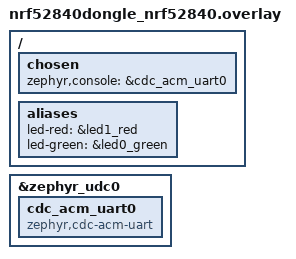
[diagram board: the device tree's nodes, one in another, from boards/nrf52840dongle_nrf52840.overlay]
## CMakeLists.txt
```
cmake_minimum_required(VERSION 3.20.0)

list(APPEND ZEPHYR_EXTRA_MODULES
	"${CMAKE_CURRENT_SOURCE_DIR}/../../libs/cookie_proto"
)

list(APPEND BOARD_ROOT "${CMAKE_CURRENT_SOURCE_DIR}/../..")
list(APPEND DTS_ROOT   "${CMAKE_CURRENT_SOURCE_DIR}/../..")

find_package(Zephyr REQUIRED HINTS $ENV{ZEPHYR_BASE})
project(cookie_gateway)

target_sources(app PRIVATE
	src/main.c
	src/coap_server.c
	src/usb_print.c
)
```

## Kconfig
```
mainmenu "Cookie gateway"

# Thread network credentials live in upstream Kconfig:
#   CONFIG_OPENTHREAD_NETWORK_NAME
#   CONFIG_OPENTHREAD_NETWORKKEY
#   CONFIG_OPENTHREAD_PANID
#   CONFIG_OPENTHREAD_XPANID
#   CONFIG_OPENTHREAD_CHANNEL
# Defaults are set in apps/gateway/prj.conf.

source "Kconfig.zephyr"
```

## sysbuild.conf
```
SB_CONFIG_BOOTLOADER_MCUBOOT=n

# Disable Partition Manager: it's deprecated in NCS v3.3 and was the actual
# cause of the SYS_INIT crash that killed every OpenThread image on
# nRF52840 Dongle. Without PM, Zephyr uses the DT-declared partitions.
SB_CONFIG_PARTITION_MANAGER=n
```

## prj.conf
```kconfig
# Cookie gateway: OpenThread FTD + Zephyr CoAP server + raw passthrough to
# the host console.
#
# Builds on both nrf52840dongle (USB-CDC console) and cookie_nrf_v200
# (hardware UART console). Per-board specifics live in
# boards/<board>.conf. CONFIG_OPENTHREAD=y pulls in the OT stack;
# Zephyr-side NETWORKING/L2/sockets/CoAP are added because the gateway
# uses Zephyr's <zephyr/net/coap.h> + BSD sockets (not OT's CoAP API).
# OT defaults auto-start; the dataset comes from CONFIG_OPENTHREAD_NETWORK*
# below.

# Core OpenThread.
CONFIG_OPENTHREAD=y

# Zephyr networking (selected explicitly; CONFIG_OPENTHREAD does not pull these
# transitively).
CONFIG_NETWORKING=y
CONFIG_NET_L2_OPENTHREAD=y
CONFIG_NET_IPV6=y
CONFIG_NET_UDP=y
CONFIG_NET_SOCKETS=y

# OT-native CoAP (replaces the Zephyr CoAP-over-socket path used in the
# old coap_server.c — Zephyr's socket layer doesn't surface multicast on
# the OT-backed stack).
CONFIG_OPENTHREAD_COAP=y

# Default Thread dataset (baked in; auto-loaded by Zephyr glue at boot).
CONFIG_OPENTHREAD_NETWORK_NAME="CookieMesh"
CONFIG_OPENTHREAD_NETWORKKEY="00:11:22:33:44:55:66:77:88:99:aa:bb:cc:dd:ee:ff"
CONFIG_OPENTHREAD_PANID=43981
CONFIG_OPENTHREAD_XPANID="de:ad:00:be:ef:00:ca:fe"
CONFIG_OPENTHREAD_CHANNEL=15

# As the headline gateway image we want to bias toward Leader/Router; bump the
# Router upgrade threshold so an early-booted Cookie gateway snaps up the
# Leader role rather than hanging at REED.
CONFIG_OPENTHREAD_MAX_CHILDREN=10

# Settings storage for OT dataset persistence.
CONFIG_PM_PARTITION_SIZE_SETTINGS_STORAGE=0x8000

# Trim mbedtls (saves ~5 KB; we don't use SHA-1 anywhere).
CONFIG_MBEDTLS_SHA1_C=n

# Console / printk for raw JSON-line emission.
# LOG_MODE_DEFERRED so the log subsystem doesn't block USB enumeration in
# SYS_INIT (IMMEDIATE mode can hang the Dongle gateway there).
CONFIG_LOG=y
CONFIG_LOG_MODE_DEFERRED=y
CONFIG_PRINTK=y
CONFIG_GPIO=y
CONFIG_CBPRINTF_FP_SUPPORT=y
CONFIG_FPU=y

# Thread-side logging kept to critical only: at INFO/DEBUG the Mle and
# MeshForwarder spam floods the console, overruns the deferred log buffer and
# truncates the JSON frames the PC tool parses. Frames (printk) also bypass the
# log subsystem so they reach the console intact regardless of log pressure.
CONFIG_OPENTHREAD_LOG_LEVEL_CRIT=y
CONFIG_OPENTHREAD_DEBUG=n
CONFIG_LOG_PRINTK=n

# Stack and main thread.
CONFIG_MAIN_STACK_SIZE=4096

# Cookie shared protocol library (frame schema, resource paths).
CONFIG_COOKIE_PROTO=y
```

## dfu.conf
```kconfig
# DFU image layout: the Nordic Open Bootloader keeps a static MBR in the first
# 4 kB of flash and its own USB bootloader at the top, so the application is
# linked at 0x1000 and handed to the board over USB with nrfutil instead of SWD.
#
# Layered on top of usb_console.conf: a gateway flashed over its own USB-C is
# also read over its own USB-C. Pairs with dfu.overlay, which moves the
# settings storage partition clear of the bootloader region at the top of
# flash.

# No MCUboot in this project (see sysbuild.conf), so the code partition in
# devicetree does not describe this image. Take the load offset from Kconfig.
CONFIG_USE_DT_CODE_PARTITION=n
CONFIG_FLASH_LOAD_OFFSET=0x1000

# The bootloader treats 0xDD000-0xDFFFF as application data: it never erases
# those pages during DFU and rejects any image that reaches past 0xDD000.
# Cap the link region so an oversized image fails at build time, not on DFU.
CONFIG_FLASH_LOAD_SIZE=0xDC000
```

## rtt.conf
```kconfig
# Single-board bring-up: route console + logging to SEGGER RTT so the
# gateway JSON-line stream and logs are read over the same J-Link/SWD probe,
# with no UART-to-USB bridge wired. The PC tool reads the RTT channel.
CONFIG_USE_SEGGER_RTT=y
CONFIG_CONSOLE=y
CONFIG_RTT_CONSOLE=y
CONFIG_UART_CONSOLE=n
CONFIG_LOG_BACKEND_RTT=y
CONFIG_LOG_BACKEND_UART=n
CONFIG_SEGGER_RTT_BUFFER_SIZE_UP=4096

# Bare-metal SWD flashing without a bootloader: the board defconfig pins
# USE_DT_CODE_PARTITION=y (image linked at slot0 = 0xC000, expecting MCUboot
# at 0x0). With no bootloader present the chip reads a blank vector table at
# 0x0 and HardFaults. Link the image at flash base 0x0 instead.
CONFIG_USE_DT_CODE_PARTITION=n
```

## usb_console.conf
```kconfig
# USB-CDC ACM console for the Cookie gateway / border router (read the whole
# mesh directly over the board's own USB-C as a COM port, no J-Link / RTT).
#
# The gateway already emits forwarded sensor frames, topology events and a
# heartbeat via printk (apps/gateway/src). This overlay just moves the console
# from the hardware UART to a USB-CDC serial port and brings USB up at boot.
# Pairs with usb_console.overlay.

CONFIG_USB_DEVICE_STACK_NEXT=y
CONFIG_USBD_CDC_ACM_CLASS=y
CONFIG_CDC_ACM_SERIAL_INITIALIZE_AT_BOOT=y
CONFIG_CDC_ACM_SERIAL_PRODUCT_STRING="Cookie Gateway"

CONFIG_SERIAL=y
CONFIG_CONSOLE=y
CONFIG_UART_CONSOLE=y
CONFIG_UART_LINE_CTRL=y

CONFIG_HWINFO=y

# No MCUboot in this project (sysbuild.conf): link at flash base 0x0 so the
# reset vector is valid when flashed straight over SWD.
CONFIG_USE_DT_CODE_PARTITION=n
```

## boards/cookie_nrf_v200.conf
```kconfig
# Cookie nRF V2.00 as gateway / Leader.
#
# Console is the on-board hardware UART (set as zephyr,console in the
# board DTS chosen{}). No USB stack is brought up; the PC tool reads the
# JSON-line stream over UART through whatever USB-to-serial bridge sits
# next to the board (or through the SWD probe's VCOM if J-Link is used).
#
# All Cookie defconfig settings (GPIO, SERIAL, CONSOLE, UART_CONSOLE,
# clocks, MPU, hardware stack protection) are sufficient. Sensor stack is
# explicitly disabled here because the gateway image does not need it.
CONFIG_SENSOR=n
CONFIG_I2C=n
CONFIG_ADC=n
CONFIG_INPUT=n
```

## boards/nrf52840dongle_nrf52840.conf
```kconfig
# Dongle as gateway. Defconfig auto-enables USB CDC ACM as the console;
# the gateway emits its JSON-line stream there via printk (see usb_print.c).
# The product-string override below is what shows up in Device Manager
# / `lsusb -v`, so the user can tell the Cookie gateway apart from a
# vanilla Dongle on a multi-port hub.
CONFIG_CDC_ACM_SERIAL_PRODUCT_STRING="Cookie Gateway"
```

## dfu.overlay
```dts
/*
 * Settings storage relocated for the Open Bootloader layout.
 *
 * The board devicetree puts the storage partition at 0xF8000, inside the
 * region the Nordic Open Bootloader occupies (roughly 0xE0000 to 0x100000).
 * OpenThread writes its network credentials there through the settings NVS
 * backend, so on a DFU image the partition moves onto the bootloader's
 * application-data area at 0xDD000-0xDFFFF (12 kB, three NVS sectors). The
 * bootloader never erases those pages during DFU and refuses any image that
 * reaches into them, so the credentials survive a firmware update and no
 * update can clobber them.
 *
 * Pairs with dfu.conf. The unit-address of the node keeps the name it was
 * given in the board devicetree; only the address in reg is authoritative.
 */

&storage_partition {
	reg = <0x000DD000 DT_SIZE_K(12)>;
};
```

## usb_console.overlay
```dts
/*
 * USB-CDC ACM console for the Cookie gateway / border router.
 *
 * Routes the gateway console (printk: forwarded sensor frames + topology
 * events + heartbeat) to a COM port on the board's own USB-C, so the whole
 * mesh is read directly over USB with no J-Link / RTT. Pairs with
 * usb_console.conf.
 */

zephyr_udc0: &usbd {
	status = "okay";

	cdc_acm_uart0: cdc_acm_uart0 {
		compatible = "zephyr,cdc-acm-uart";
	};
};

/ {
	chosen {
		zephyr,console = &cdc_acm_uart0;
	};
};
```

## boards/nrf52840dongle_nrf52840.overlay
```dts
/ {
	chosen {
		zephyr,console = &cdc_acm_uart0;
	};

	aliases {
		led-red   = &led1_red;
		led-green = &led0_green;
	};
};

&zephyr_udc0 {
	cdc_acm_uart0: cdc_acm_uart0 {
		compatible = "zephyr,cdc-acm-uart";
	};
};
```

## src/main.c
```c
/*
 * Cookie gateway entry point.
 *
 * OpenThread is auto-started by the Zephyr glue (no MANUAL_START), with the
 * dataset taken from CONFIG_OPENTHREAD_NETWORK_NAME / NETWORKKEY / PANID /
 * XPANID / CHANNEL in prj.conf. Once the L2 is up, this module starts the
 * Zephyr CoAP server bound on UDP 5683 and toggles the green LED as a
 * heartbeat. Frame payloads are passed through verbatim to USB-CDC.
 */

#include <zephyr/kernel.h>
#include <zephyr/logging/log.h>
#include <zephyr/drivers/gpio.h>
#include <zephyr/net/openthread.h>

#include <openthread/instance.h>
#include <openthread/thread.h>
#include <openthread/link.h>

#include <stdio.h>

#include "coap_server.h"
#include "usb_print.h"

LOG_MODULE_REGISTER(gateway, LOG_LEVEL_INF);

static void ext_last4(const otExtAddress *ext, char out[5])
{
	snprintf(out, 5, "%02x%02x", ext->m8[6], ext->m8[7]);
}

/* Emit the gateway's view of the mesh as a topology event the PC tool draws:
 *   {"event":"topology","tree":{"<gw>":["<neighbour>", ...]}}
 * Node IDs are the EUI-64 last two bytes, matching the `src` field of sensor
 * frames so the tree lines up with the live table. The gateway reports its
 * direct neighbours (one radio hop); for the small demo mesh that is the whole
 * network. printk goes straight to the console (CONFIG_LOG_PRINTK=n) so the
 * line is never truncated by log-buffer pressure. */
static void emit_topology(otInstance *inst)
{
	const otExtAddress *self = otLinkGetExtendedAddress(inst);
	char gw[5];
	ext_last4(self, gw);

	char line[256];
	int off = snprintf(line, sizeof(line),
			   "{\"event\":\"topology\",\"tree\":{\"%s\":[", gw);

	otNeighborInfoIterator it = OT_NEIGHBOR_INFO_ITERATOR_INIT;
	otNeighborInfo info;
	bool first = true;
	while (off < (int)sizeof(line) - 8 &&
	       otThreadGetNextNeighborInfo(inst, &it, &info) == OT_ERROR_NONE) {
		char nb[5];
		ext_last4(&info.mExtAddress, nb);
		off += snprintf(line + off, sizeof(line) - off,
				"%s\"%s\"", first ? "" : ",", nb);
		first = false;
	}
	snprintf(line + off, sizeof(line) - off, "]}}");
	printk("%s\n", line);
}

static const struct gpio_dt_spec led_red =
	GPIO_DT_SPEC_GET_OR(DT_ALIAS(led_red), gpios, {0});
static const struct gpio_dt_spec led_green =
	GPIO_DT_SPEC_GET_OR(DT_ALIAS(led_green), gpios, {0});

static void on_thread_state_changed(otChangedFlags flags, void *user_data)
{
	ARG_UNUSED(user_data);

	if (flags & OT_CHANGED_THREAD_ROLE) {
		otDeviceRole role = otThreadGetDeviceRole(openthread_get_default_instance());
		LOG_INF("Thread role: %s", otThreadDeviceRoleToString(role));
		if (led_red.port) {
			bool attached = (role == OT_DEVICE_ROLE_LEADER ||
					 role == OT_DEVICE_ROLE_ROUTER ||
					 role == OT_DEVICE_ROLE_CHILD);
			gpio_pin_set_dt(&led_red, attached ? 1 : 0);
		}
	}
}

static struct openthread_state_changed_callback ot_state_cb = {
	.otCallback = on_thread_state_changed,
};

int main(void)
{
	LOG_INF("Cookie gateway: board=%s", CONFIG_BOARD);

	if (led_red.port) {
		gpio_pin_configure_dt(&led_red, GPIO_OUTPUT_INACTIVE);
	}
	if (led_green.port) {
		gpio_pin_configure_dt(&led_green, GPIO_OUTPUT_INACTIVE);
	}

	gateway_usb_print_init();

	/* Persistent OT state is kept across reboots so the gateway holds its
	 * partition and the mesh heals correctly per the Thread spec. The
	 * one-time clean wipe lives behind CONFIG_COOKIE_FACTORY_RESET_ON_BOOT
	 * for clearing stale datasets from earlier experiments. */
#if defined(CONFIG_COOKIE_FACTORY_RESET_ON_BOOT)
	{
		otInstance *inst = openthread_get_default_instance();
		if (inst) {
			otThreadSetEnabled(inst, false);
			otIp6SetEnabled(inst, false);
			(void)otInstanceErasePersistentInfo(inst);
			LOG_INF("OT persistent info erased (factory-reset on boot)");
		}
	}
#endif

	openthread_state_changed_callback_register(&ot_state_cb);

	int orc = openthread_run();
	if (orc) {
		LOG_ERR("openthread_run: %d", orc);
		return -1;
	}

	if (gateway_coap_server_start() != 0) {
		LOG_ERR("CoAP server start failed");
		return -1;
	}

	uint32_t tick = 0;
	while (1) {
		if (led_green.port) {
			gpio_pin_toggle_dt(&led_green);
		}
		k_sleep(K_MSEC(1000));
		if ((++tick % 5) == 0) {
			otInstance *inst = openthread_get_default_instance();
			if (inst) {
				LOG_INF("heartbeat tick=%u role=%s",
					tick,
					otThreadDeviceRoleToString(otThreadGetDeviceRole(inst)));
				emit_topology(inst);
			}
		}
	}
	return 0;
}
```

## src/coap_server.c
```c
/*
 * Stub CoAP server (#2a), now on OpenThread native CoAP API.
 *
 * Listens on UDP 5683 via OT's CoAP layer (no Zephyr socket plumbing).
 * Accepts POST /sensors/data, prints the payload as a JSON line on the
 * host console, and replies with ACK 2.04 if the request was CON.
 *
 * Why OT-native CoAP and not Zephyr CoAP-over-socket: the Zephyr UDP
 * socket bound to AF_INET6 ANY does not receive multicast packets even
 * after IPV6_ADD_MEMBERSHIP / IPV6_JOIN_GROUP / net_if_ipv6_maddr_add
 * (all return ENOTSUP / NULL on the OT-backed stack). OT's CoAP layer
 * subscribes to the right Thread groups internally and surfaces every
 * matching request to our handler.
 *
 * #4 will replace this handler with one that parses the frame, decorates
 * with ts_host, emits structured event lines, etc. The interface stays
 * compatible (single-resource registration is the public surface).
 */

#include "coap_server.h"
#include "usb_print.h"

#include <cookie_proto/resources.h>

#include <zephyr/kernel.h>
#include <zephyr/logging/log.h>
#include <zephyr/net/openthread.h>

#include <openthread/coap.h>
#include <openthread/error.h>
#include <openthread/instance.h>
#include <openthread/message.h>

#include <errno.h>
#include <string.h>

LOG_MODULE_REGISTER(coap_server, LOG_LEVEL_INF);

#define COAP_PORT      5683
#define MAX_PAYLOAD    512

static otCoapResource sensors_resource = {
	.mUriPath = COOKIE_RESOURCE_SENSORS_PATH,   /* "sensors/data" */
	.mHandler = NULL,                            /* set in start() */
	.mContext = NULL,
	.mNext    = NULL,
};

/* Send a 2.04 Changed response back to the requester.
 *   - CON request -> piggyback ACK (same message ID)
 *   - NON request -> NON response (fresh message ID)
 * NON responses are required for our discovery flow: when the sensor sends
 * a NON multicast POST, gateway must answer with a NON unicast so the
 * sensor can cache the gateway's address from the response source. */
static otError send_response_changed(otInstance *ot,
				     const otMessage *request,
				     const otMessageInfo *info)
{
	otCoapType req_type = otCoapMessageGetType(request);
	otCoapType rsp_type = (req_type == OT_COAP_TYPE_CONFIRMABLE)
			      ? OT_COAP_TYPE_ACKNOWLEDGMENT
			      : OT_COAP_TYPE_NON_CONFIRMABLE;

	otMessage *response = otCoapNewMessage(ot, NULL);
	if (!response) {
		return OT_ERROR_NO_BUFS;
	}

	otError err = otCoapMessageInitResponse(response, request, rsp_type,
						OT_COAP_CODE_CHANGED);
	if (err != OT_ERROR_NONE) {
		otMessageFree(response);
		return err;
	}

	err = otCoapSendResponse(ot, response, info);
	if (err != OT_ERROR_NONE) {
		otMessageFree(response);
	}
	return err;
}

static void sensors_post_handler(void *ctx,
				 otMessage *message,
				 const otMessageInfo *message_info)
{
	ARG_UNUSED(ctx);

	if (otCoapMessageGetCode(message) != OT_COAP_CODE_POST) {
		LOG_DBG("ignoring non-POST on /sensors/data");
		return;
	}

	uint16_t off = otMessageGetOffset(message);
	uint16_t total = otMessageGetLength(message);
	uint16_t plen = (total > off) ? (total - off) : 0;

	if (plen > 0) {
		uint8_t buf[MAX_PAYLOAD];
		uint16_t copy = (plen <= sizeof(buf)) ? plen : sizeof(buf);
		uint16_t got = otMessageRead(message, off, buf, copy);
		gateway_usb_print_line(buf, got);
	} else {
		LOG_WRN("empty POST /sensors/data, ignoring");
	}

	/* Always respond — NON gets a NON response, CON gets a piggyback
	 * ACK. The sensor's discovery flow needs a NON response back so it
	 * can cache our address from the source field. */
	otInstance *ot = openthread_get_default_instance();
	(void)send_response_changed(ot, message, message_info);
}

static void default_handler(void *ctx,
			    otMessage *message,
			    const otMessageInfo *message_info)
{
	ARG_UNUSED(ctx);
	ARG_UNUSED(message);
	ARG_UNUSED(message_info);
	LOG_DBG("unmatched CoAP request");
}

int gateway_coap_server_start(void)
{
	otInstance *ot = openthread_get_default_instance();
	if (!ot) {
		LOG_ERR("no OT instance");
		return -ENODEV;
	}

	sensors_resource.mHandler = sensors_post_handler;
	sensors_resource.mContext = NULL;

	otCoapSetDefaultHandler(ot, default_handler, NULL);
	otCoapAddResource(ot, &sensors_resource);

	otError err = otCoapStart(ot, COAP_PORT);
	if (err != OT_ERROR_NONE) {
		LOG_ERR("otCoapStart: %d", err);
		return -EIO;
	}

	LOG_INF("OT-CoAP server listening on UDP %d, resource %s",
		COAP_PORT, sensors_resource.mUriPath);
	return 0;
}
```

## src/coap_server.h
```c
#ifndef GATEWAY_COAP_SERVER_H_
#define GATEWAY_COAP_SERVER_H_

/**
 * Open a UDP socket on the CoAP port, register the /sensors/data
 * resource, and start a dedicated thread that runs the recv loop.
 *
 * @return 0 on success, negative errno on failure.
 */
int gateway_coap_server_start(void);

#endif /* GATEWAY_COAP_SERVER_H_ */
```

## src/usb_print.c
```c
/*
 * Raw JSON-line emission on the host console (USB-CDC on Dongle).
 *
 * #2a stub: payload bytes verbatim + '\n'. Log lines from CONFIG_LOG
 * share the same console; the PC tool discriminates by leading '{' for
 * frames vs '[' for log timestamps.
 */

#include "usb_print.h"

#include <zephyr/kernel.h>
#include <zephyr/sys/printk.h>

static K_MUTEX_DEFINE(print_lock);

void gateway_usb_print_init(void)
{
	/* Console is brought up by the Dongle defconfig (USB-CDC ACM).
	 * Nothing extra to do here; init exists so future tweaks (line
	 * mode, locked output buffer, etc.) have a clear home. */
}

void gateway_usb_print_line(const uint8_t *payload, size_t len)
{
	k_mutex_lock(&print_lock, K_FOREVER);
	for (size_t i = 0; i < len; i++) {
		printk("%c", payload[i]);
	}
	printk("\n");
	k_mutex_unlock(&print_lock);
}
```

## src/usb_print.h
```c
#ifndef GATEWAY_USB_PRINT_H_
#define GATEWAY_USB_PRINT_H_

#include <stddef.h>
#include <stdint.h>

void gateway_usb_print_init(void);

/**
 * Emit one JSON line on the host-facing console: payload bytes verbatim
 * followed by '\n'. Safe to call from any thread; output is serialised
 * by the underlying console backend.
 */
void gateway_usb_print_line(const uint8_t *payload, size_t len);

#endif /* GATEWAY_USB_PRINT_H_ */
```
